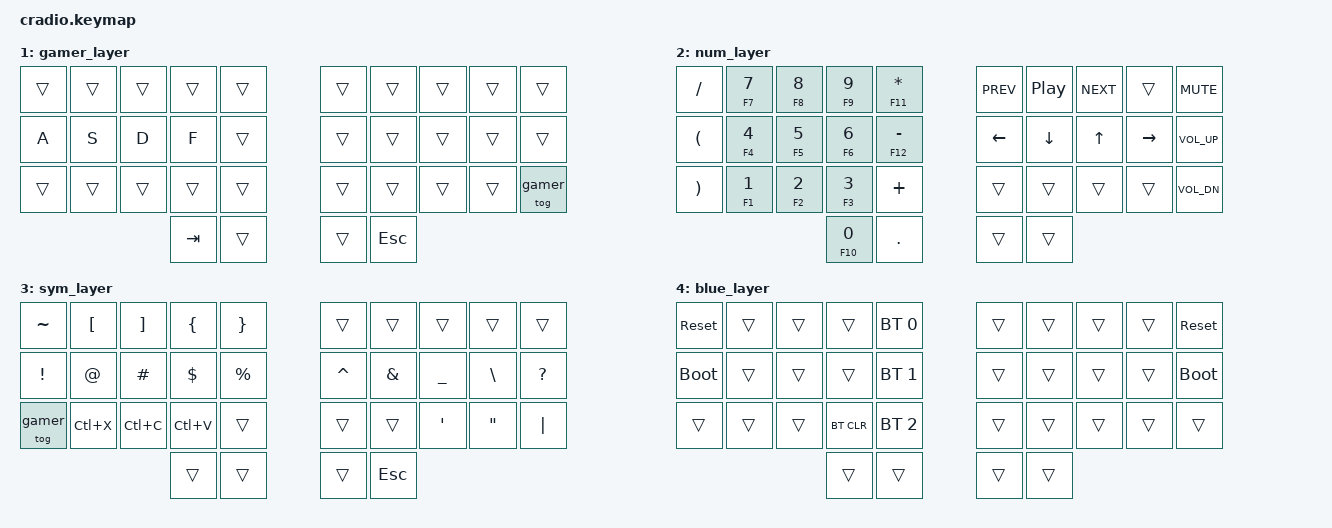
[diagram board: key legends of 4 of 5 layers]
// Copyright (c) 2022 The ZMK Contributors
// SPDX-License-Identifier: MIT

#include <behaviors.dtsi>
#include <dt-bindings/zmk/keys.h>
#include <dt-bindings/zmk/bt.h>

// Home row mods macro&trans
#define HRML(k1,k2,k3,k4) &ht LSHFT k1  &ht LALT k2  &ht LCTRL k3  &ht LGUI k4
#define HRMR(k1,k2,k3,k4) &ht RGUI k1  &ht LCTRL k2  &ht RALT k3  &ht RSHFT k4
#define DEFAULT 0
#define gamer   1
#define num     2
#define sym     3
#define blue    4
/ {
    behaviors {
        ht: hold_tap {
            label = "hold_tap";
            compatible = "zmk,behavior-hold-tap";
            #binding-cells = <2>;
            flavor = "tap-preferred";
            tapping-term-ms = <220>;
            quick-tap-ms = <150>;
            global-quick-tap;
            bindings = <&kp>, <&kp>;
        };
    };

    conditional_layers {
       compatible = "zmk,conditional-layers";
      tri_layer {
           if-layers = <sym num>;
           then-layer = <blue>;
       };
    };

    keymap {
        compatible = "zmk,keymap";
        default_layer {
            bindings = <
        //╭──────────┬──────────┬──────────┬──────────┬──────────╮   ╭──────────┬──────────┬──────────┬──────────┬──────────╮
        //│  Q       │  W       │  E       │  R       │  T       │   │  Y       │  U       │  I       │  O       │  P       │
            &kp Q      &kp W      &kp E      &kp R      &kp T          &kp Y      &kp U      &kp I      &kp O      &kp P
        //├──────────┼──────────┼──────────┼──────────┼──────────┤   ├──────────┼──────────┼──────────┼──────────┼──────────┤
        //│  A       │  S       │  D       │  F       │  G       │   │  H       │  J       │  K       │  L       │ ; :      │
            HRML(A,        S,         D,         F)     &kp G          &kp H      HRMR(J,        K,         L,        SEMI)
        //├──────────┼──────────┼──────────┼──────────┼──────────┤   ├──────────┼──────────┼──────────┼──────────┼──────────┤
        //│  Z       │  X       │  C       │  V       │  B       │   │  N       │  M       │ , <      │ . >      │   delete │
            &kp Z      &kp X      &kp C      &kp V      &kp B          &kp N      &kp M      &kp COMMA  &kp DOT    &kp DEL
        //╰──────────┴──────────┴──────────┼──────────┼──────────┤   ├──────────┼──────────┼──────────┴──────────┴──────────╯
                                            &lt sym TAB   &kp SPACE  &lt num ENTER &kp BSPC
        //                                 ╰──────────┴──────────╯   ╰──────────┴──────────╯
            >;
        };
        gamer_layer {
            bindings = <
        //╭──────────┬──────────┬──────────┬──────────┬──────────╮   ╭──────────┬──────────┬──────────┬──────────┬──────────╮
        //│          │          │          │          │          │   │          │          │          │          │         │
            &trans     &trans     &trans     &trans        &trans       &trans     &trans     &trans     &trans    &trans
        //├──────────┼──────────┼──────────┼──────────┼──────────┤   ├──────────┼──────────┼──────────┼──────────┼──────────┤
        //│          │          │          │          │          │   │          │          │          │          │          │
             &kp A      &kp S       &kp D     &kp F      &trans         &trans     &trans     &trans     &trans     &trans
        //├──────────┼──────────┼──────────┼──────────┼──────────┤   ├──────────┼──────────┼──────────┼──────────┼──────────┤
        //│          │          │          │          │          │   │          │          │          │          │          │
            &trans     &trans     &trans      &trans    &trans          &trans     &trans     &trans     &trans   &tog gamer 
        //╰──────────┴──────────┴──────────┼──────────┼──────────┤   ├──────────┼──────────┼──────────┴──────────┴──────────╯
                                             &kp TAB     &trans         &trans    &kp ESC  
        //                                 ╰──────────┴──────────╯   ╰──────────┴──────────╯
            >;
        };
        num_layer {
            bindings = <
        //╭──────────┬──────────┬──────────┬──────────┬──────────╮   ╭──────────┬──────────┬──────────┬──────────┬──────────╮
        //│ /        │  7       │  8       │  9       │     *    │   │          │    play  │          │          │          │
            &kp FSLH  &mt F7 N7  &mt F8 N8  &mt F9 N9  &mt F11 ASTRK  &kp C_PREV  &kp C_PP  &kp C_NEXT  &trans    &kp C_MUTE
        //├──────────┼──────────┼──────────┼──────────┼──────────┤   ├──────────┼──────────┼──────────┼──────────┼──────────┤
        //│ (        │  4       │  5       │  6       │    -     │   │ LEFT     │ DOWN     │ UP       │ RIGHT    │          │
           &kp LPAR   &mt F4 N4  &mt F5 N5  &mt F6 N6 &mt F12 MINUS   &kp LEFT   &kp DOWN   &kp UP   &kp RIGHT  &kp C_VOL_UP
        //├──────────┼──────────┼──────────┼──────────┼──────────┤   ├──────────┼──────────┼──────────┼──────────┼──────────┤
        //│ )        │  1       │  2       │  3       │   +      │   │          │          │          │          │          │
           &kp RPAR   &mt F1 N1  &mt F2 N2  &mt F3 N3  &kp PLUS         &trans     &trans      &trans     &trans &kp C_VOL_DN
        //╰──────────┴──────────┴──────────┼──────────┼──────────┤   ├──────────┼──────────┼──────────┴──────────┴──────────╯
        //                                       0         .
                                            &mt F10 N0 &kp DOT        &trans     &trans
        //                                 ╰──────────┴──────────╯   ╰──────────┴──────────╯
            >;
        };

        sym_layer {
            bindings = <
        //╭──────────┬──────────┬──────────┬──────────┬──────────╮   ╭──────────┬──────────┬──────────┬──────────┬──────────╮
        //│    ~     │  [       │     ]    │      {   │     }    │   │          │          │          │          │          │
           &kp TILDE    &kp LBKT  &kp RBKT   &kp LBRC   &kp RBRC       &trans     &trans     &trans     &trans     &trans 
        //├──────────┼──────────┼──────────┼──────────┼──────────┤   ├──────────┼──────────┼──────────┼──────────┼──────────┤
        //│  !       │  @       │  #       │  $       │  %       │   │     ^    │   &      │    _     │  \       │      ?   │
            &kp EXCL   &kp AT     &kp HASH   &kp DLLR   &kp PRCNT      &kp CARET &kp AMPS    &kp UNDER  &kp BSLH   &kp QMARK
        //├──────────┼──────────┼──────────┼──────────┼──────────┤   ├──────────┼──────────┼──────────┼──────────┼──────────┤
        //│  gamer   │ cut      │copy      │  paste   │          │   │          │          │     '    │  "       │    |     │
           &tog gamer     &kp LC(X)  &kp LC(C)  &kp LC(V)   &trans         &trans     &trans    &kp SQT   &kp DQT   &kp PIPE
        //╰──────────┴──────────┴──────────┼──────────┼──────────┤   ├──────────┼──────────┼──────────┴──────────┴──────────╯
                                             &trans     &trans         &trans     &kp ESC
        //                                 ╰──────────┴──────────╯   ╰──────────┴──────────╯                                        
            >;
        };

        blue_layer {
            bindings = <
        //╭──────────┬──────────┬──────────┬──────────┬──────────╮   ╭──────────┬──────────┬──────────┬──────────┬──────────╮
        //│ RESET    │          │          │          │PROFILE 0 │   │          │          │          │          │  RESET   │
            &sys_reset     &trans     &trans     &trans    &bt BT_SEL 0    &trans     &trans     &trans     &trans  &sys_reset
        //├──────────┼──────────┼──────────┼──────────┼──────────┤   ├──────────┼──────────┼──────────┼──────────┼──────────┤
        //│BOOTLOADER│          │          │          │PROFILE 1 │   │          │          │          │          │BOOTLOADER│
          &bootloader  &trans     &trans     &trans    &bt BT_SEL 1    &trans     &trans     &trans     &trans    &bootloader
        //├──────────┼──────────┼──────────┼──────────┼──────────┤   ├──────────┼──────────┼──────────┼──────────┼──────────┤
        //│          │          │          │ CLEAR BT │PROFILE 2 │   │          │          │          │          │          │
            &trans     &trans     &trans    &bt BT_CLR &bt BT_SEL 2    &trans     &trans     &trans     &trans     &trans
        //╰──────────┴──────────┴──────────┼──────────┼──────────┤   ├──────────┼──────────┼──────────┴──────────┴──────────╯
                                             &trans     &trans         &trans     &trans
        //                                 ╰──────────┴──────────╯   ╰──────────┴──────────╯
            >;
        };
        
    };
};
